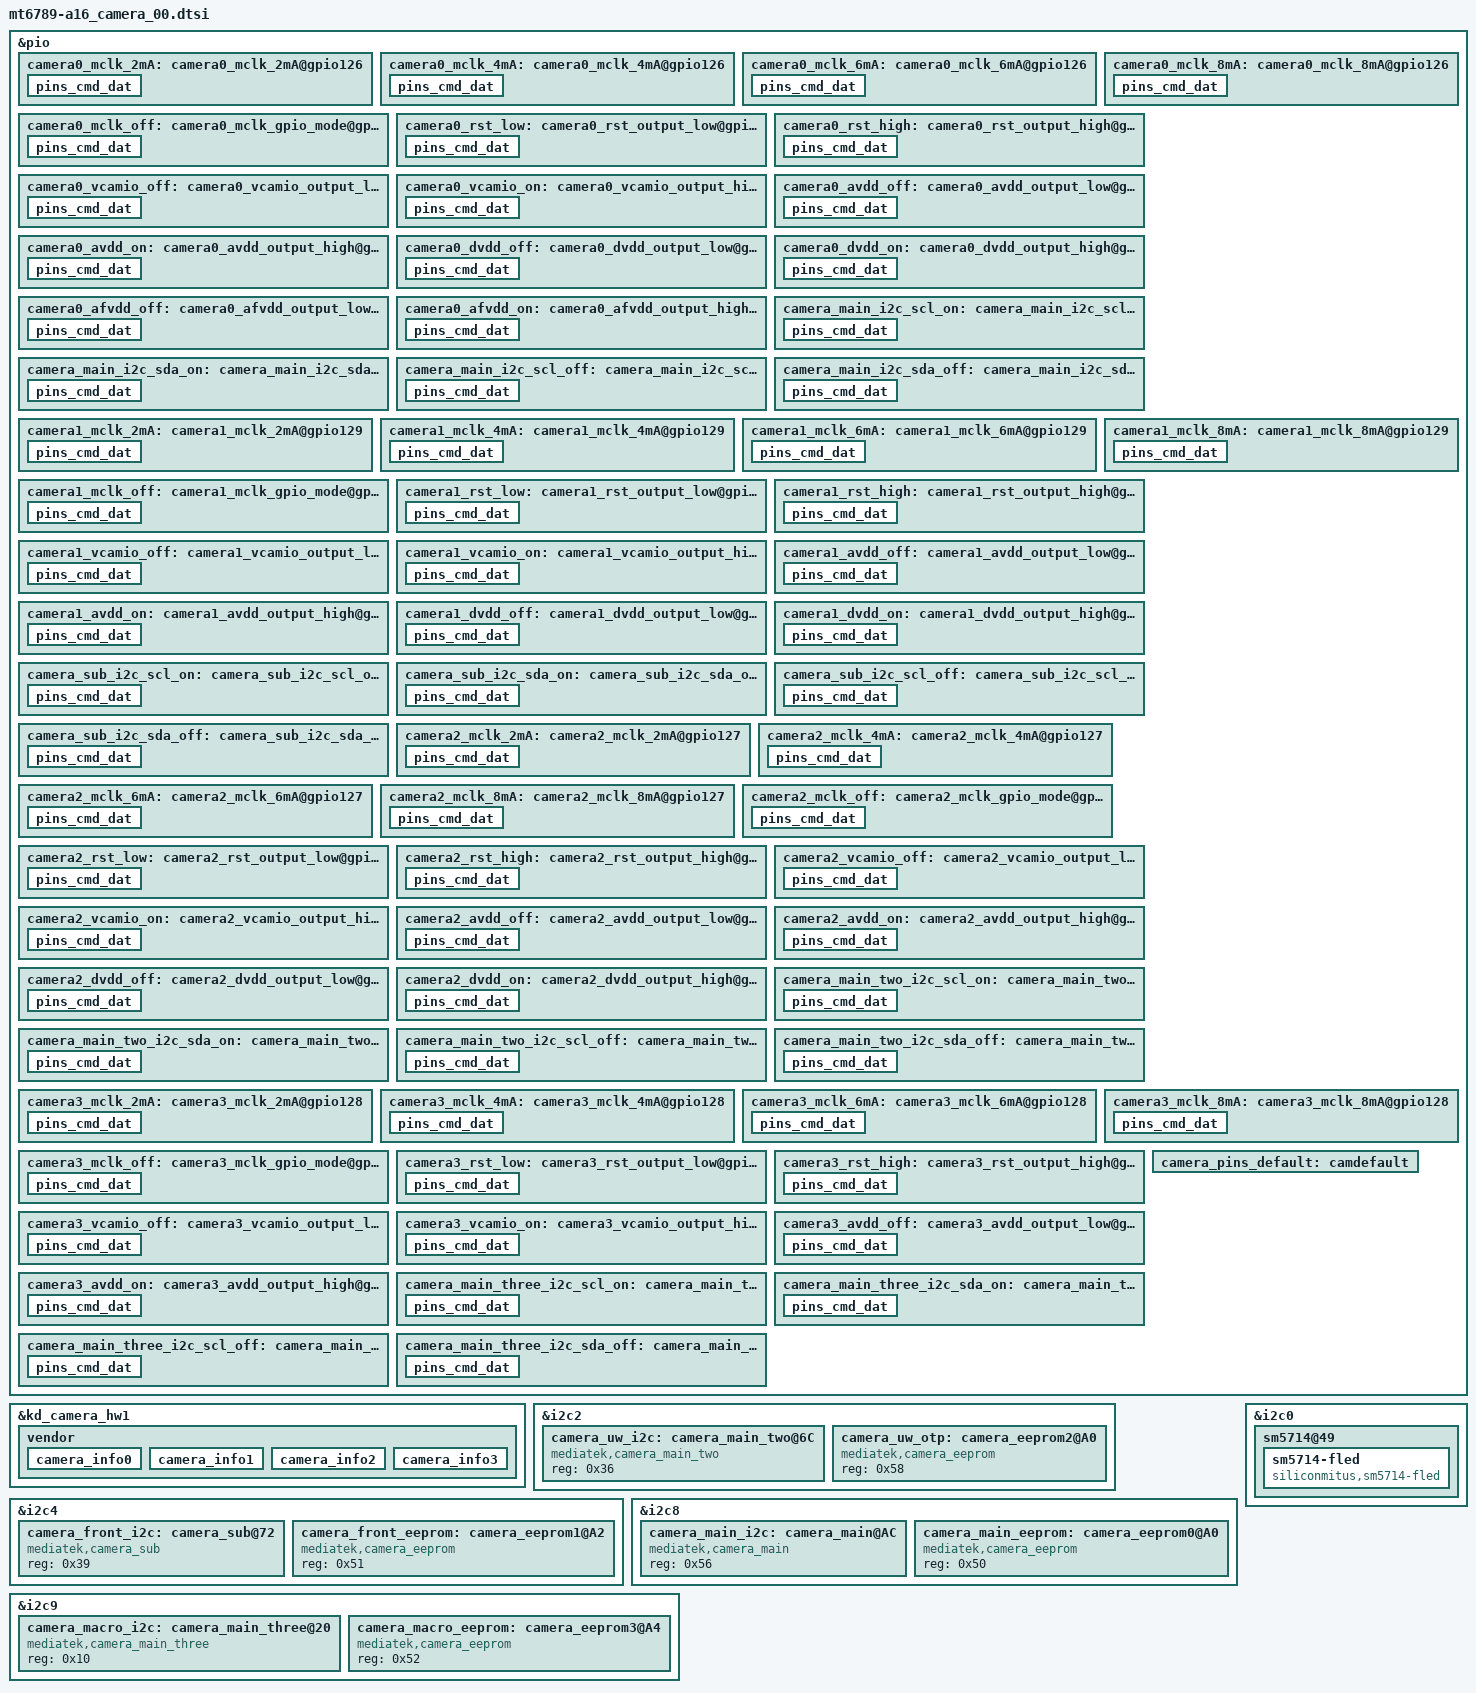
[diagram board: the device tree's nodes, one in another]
/*
 * Copyright (c) 2023 MediaTek Inc.
 *
 * This program is free software; you can redistribute it and/or modify
 * it under the terms of the GNU General Public License version 2 as
 * published by the Free Software Foundation.
 *
 * This program is distributed in the hope that it will be useful,
 * but WITHOUT ANY WARRANTY; without even the implied warranty of
 * MERCHANTABILITY or FITNESS FOR A PARTICULAR PURPOSE.  See the
 * GNU General Public License for more details.
 */

/********  A16-LTE Board  ***********
 *    SW          :   HW   : Sensor
 * camera0(Wide)  : RCAM1  : S5KJN1
 * camera1(Front) : FCAM   : GC13A0
 * camera2(UW)    : RCAM2  : SC501CS
 * camera3(Macro) : RCAM3  : GC02M2
 ***********************************/

/* CAMERA GPIO standardization */
&pio {
	/****************  Camera0  ***************/
	// MCLK
	camera0_mclk_2mA: camera0_mclk_2mA@gpio126 {
		pins_cmd_dat {
			pinmux = <PINMUX_GPIO126__FUNC_CMMCLK0>;
			drive-strength = <0>;
		};
	};
	camera0_mclk_4mA: camera0_mclk_4mA@gpio126 {
		pins_cmd_dat {
			pinmux = <PINMUX_GPIO126__FUNC_CMMCLK0>;
			drive-strength = <1>;
		};
	};
	camera0_mclk_6mA: camera0_mclk_6mA@gpio126 {
		pins_cmd_dat {
			pinmux = <PINMUX_GPIO126__FUNC_CMMCLK0>;
			drive-strength = <2>;
		};
	};
	camera0_mclk_8mA: camera0_mclk_8mA@gpio126 {
		pins_cmd_dat {
			pinmux = <PINMUX_GPIO126__FUNC_CMMCLK0>;
			drive-strength = <3>;
		};
	};
	camera0_mclk_off: camera0_mclk_gpio_mode@gpio126 {
		pins_cmd_dat {
			pinmux = <PINMUX_GPIO126__FUNC_GPIO126>;
			drive-strength = <3>;
		};
	};

	// Reset
	camera0_rst_low: camera0_rst_output_low@gpio16 {
		pins_cmd_dat {
			pinmux = <PINMUX_GPIO16__FUNC_GPIO16>;
			output-low;
		};
	};
	camera0_rst_high: camera0_rst_output_high@gpio16 {
		pins_cmd_dat {
			pinmux = <PINMUX_GPIO16__FUNC_GPIO16>;
			output-high;
		};
	};

	// IOVDD
	camera0_vcamio_off: camera0_vcamio_output_low@gpio108 {
		pins_cmd_dat {
			pinmux = <PINMUX_GPIO108__FUNC_GPIO108>;
			output-low;
		};
	};
	camera0_vcamio_on: camera0_vcamio_output_high@gpio108 {
		pins_cmd_dat {
			pinmux = <PINMUX_GPIO108__FUNC_GPIO108>;
			output-high;
		};
	};

	// AVDD
	camera0_avdd_off: camera0_avdd_output_low@gpio107 {
		pins_cmd_dat {
			pinmux = <PINMUX_GPIO107__FUNC_GPIO107>;
			output-low;
		};
	};
	camera0_avdd_on: camera0_avdd_output_high@gpio107 {
		pins_cmd_dat {
			pinmux = <PINMUX_GPIO107__FUNC_GPIO107>;
			output-high;
		};
	};
	// DVDD
	camera0_dvdd_off: camera0_dvdd_output_low@gpio107 {
		pins_cmd_dat {
			pinmux = <PINMUX_GPIO107__FUNC_GPIO107>;
			output-low;
		};
	};
	camera0_dvdd_on: camera0_dvdd_output_high@gpio107 {
		pins_cmd_dat {
			pinmux = <PINMUX_GPIO107__FUNC_GPIO107>;
			output-high;
		};
	};
	// AFVDD
	camera0_afvdd_off: camera0_afvdd_output_low@gpio107 {
		pins_cmd_dat {
			pinmux = <PINMUX_GPIO107__FUNC_GPIO107>;
			output-low;
		};
	};
	camera0_afvdd_on: camera0_afvdd_output_high@gpio107 {
		pins_cmd_dat {
			pinmux = <PINMUX_GPIO107__FUNC_GPIO107>;
			output-high;
		};
	};

	// I2C
	camera_main_i2c_scl_on: camera_main_i2c_scl_on@gpio146 {
		pins_cmd_dat {
			pinmux = <PINMUX_GPIO146__FUNC_SCL8>;
			bias-disable;
		};
	};
	camera_main_i2c_sda_on: camera_main_i2c_sda_on@gpio147 {
		pins_cmd_dat {
			pinmux = <PINMUX_GPIO147__FUNC_SDA8>;
			bias-disable;
		};
	};
	camera_main_i2c_scl_off: camera_main_i2c_scl_off@gpio146 {
		pins_cmd_dat {
			pinmux = <PINMUX_GPIO146__FUNC_GPIO146>;
			bias-disable;
		};
	};
	camera_main_i2c_sda_off: camera_main_i2c_sda_off@gpio147 {
		pins_cmd_dat {
			pinmux = <PINMUX_GPIO147__FUNC_GPIO147>;
			bias-disable;
		};
	};


	/****************  Camera1  ***************/
	// MCLK
	camera1_mclk_2mA: camera1_mclk_2mA@gpio129 {
		pins_cmd_dat {
			pinmux = <PINMUX_GPIO129__FUNC_CMMCLK3>;
			drive-strength = <0>;
		};
	};
	camera1_mclk_4mA: camera1_mclk_4mA@gpio129 {
		pins_cmd_dat {
			pinmux = <PINMUX_GPIO129__FUNC_CMMCLK3>;
			drive-strength = <1>;
		};
	};
	camera1_mclk_6mA: camera1_mclk_6mA@gpio129 {
		pins_cmd_dat {
			pinmux = <PINMUX_GPIO129__FUNC_CMMCLK3>;
			drive-strength = <2>;
		};
	};
	camera1_mclk_8mA: camera1_mclk_8mA@gpio129 {
		pins_cmd_dat {
			pinmux = <PINMUX_GPIO129__FUNC_CMMCLK3>;
			drive-strength = <3>;
		};
	};
	camera1_mclk_off: camera1_mclk_gpio_mode@gpio129 {
		pins_cmd_dat {
			pinmux = <PINMUX_GPIO129__FUNC_GPIO129>;
			drive-strength = <1>;
		};
	};

	// Reset
	camera1_rst_low: camera1_rst_output_low@gpio15 {
		pins_cmd_dat {
			pinmux = <PINMUX_GPIO15__FUNC_GPIO15>;
			output-low;
		};
	};
	camera1_rst_high: camera1_rst_output_high@gpio15 {
		pins_cmd_dat {
			pinmux = <PINMUX_GPIO15__FUNC_GPIO15>;
			output-high;
		};
	};

	// IOVDD
	camera1_vcamio_off: camera1_vcamio_output_low@gpio108 {
		pins_cmd_dat {
			pinmux = <PINMUX_GPIO108__FUNC_GPIO108>;
			output-low;
		};
	};
	camera1_vcamio_on: camera1_vcamio_output_high@gpio108 {
		pins_cmd_dat {
			pinmux = <PINMUX_GPIO108__FUNC_GPIO108>;
			output-high;
		};
	};

	// AVDD
	camera1_avdd_off: camera1_avdd_output_low@gpio153 {
		pins_cmd_dat {
			pinmux = <PINMUX_GPIO153__FUNC_GPIO153>;
			output-low;
		};
	};
	camera1_avdd_on: camera1_avdd_output_high@gpio153 {
		pins_cmd_dat {
			pinmux = <PINMUX_GPIO153__FUNC_GPIO153>;
			output-high;
		};
	};
	// DVDD
	camera1_dvdd_off: camera1_dvdd_output_low@gpio153 {
		pins_cmd_dat {
			pinmux = <PINMUX_GPIO153__FUNC_GPIO153>;
			output-low;
		};
	};
	camera1_dvdd_on: camera1_dvdd_output_high@gpio153 {
		pins_cmd_dat {
			pinmux = <PINMUX_GPIO153__FUNC_GPIO153>;
			output-high;
		};
	};

	// I2C
	camera_sub_i2c_scl_on: camera_sub_i2c_scl_on@gpio138 {
		pins_cmd_dat {
			pinmux = <PINMUX_GPIO138__FUNC_SCL4>;
			bias-pull-up;
		};
	};
	camera_sub_i2c_sda_on: camera_sub_i2c_sda_on@gpio139 {
		pins_cmd_dat {
			pinmux = <PINMUX_GPIO139__FUNC_SDA4>;
			bias-pull-up;
		};
	};
	camera_sub_i2c_scl_off: camera_sub_i2c_scl_off@gpio138 {
		pins_cmd_dat {
			pinmux = <PINMUX_GPIO138__FUNC_GPIO138>;
			bias-pull-down;
		};
	};
	camera_sub_i2c_sda_off: camera_sub_i2c_sda_off@gpio139 {
		pins_cmd_dat {
			pinmux = <PINMUX_GPIO139__FUNC_GPIO139>;
			bias-pull-down;
		};
	};

	/****************  Camera2  ***************/
	// MCLK
	camera2_mclk_2mA: camera2_mclk_2mA@gpio127 {
		pins_cmd_dat {
			pinmux = <PINMUX_GPIO127__FUNC_CMMCLK1>;
			drive-strength = <0>;
		};
	};
	camera2_mclk_4mA: camera2_mclk_4mA@gpio127 {
		pins_cmd_dat {
			pinmux = <PINMUX_GPIO127__FUNC_CMMCLK1>;
			drive-strength = <1>;
		};
	};
	camera2_mclk_6mA: camera2_mclk_6mA@gpio127 {
		pins_cmd_dat {
			pinmux = <PINMUX_GPIO127__FUNC_CMMCLK1>;
			drive-strength = <2>;
		};
	};
	camera2_mclk_8mA: camera2_mclk_8mA@gpio127 {
		pins_cmd_dat {
			pinmux = <PINMUX_GPIO127__FUNC_CMMCLK1>;
			drive-strength = <3>;
		};
	};
	camera2_mclk_off: camera2_mclk_gpio_mode@gpio127 {
		pins_cmd_dat {
			pinmux = <PINMUX_GPIO127__FUNC_GPIO127>;
			drive-strength = <1>;
		};
	};

	// Reset
	camera2_rst_low: camera2_rst_output_low@gpio18 {
		pins_cmd_dat {
			pinmux = <PINMUX_GPIO18__FUNC_GPIO18>;
			output-low;
		};
	};
	camera2_rst_high: camera2_rst_output_high@gpio18 {
		pins_cmd_dat {
			pinmux = <PINMUX_GPIO18__FUNC_GPIO18>;
			output-high;
		};
	};

	// IOVDD
	camera2_vcamio_off: camera2_vcamio_output_low@gpio108 {
		pins_cmd_dat {
			pinmux = <PINMUX_GPIO108__FUNC_GPIO108>;
			output-low;
		};
	};
	camera2_vcamio_on: camera2_vcamio_output_high@gpio108 {
		pins_cmd_dat {
			pinmux = <PINMUX_GPIO108__FUNC_GPIO108>;
			output-high;
		};
	};

	// AVDD
	camera2_avdd_off: camera2_avdd_output_low@gpio153 {
		pins_cmd_dat {
			pinmux = <PINMUX_GPIO153__FUNC_GPIO153>;
			output-low;
		};
	};
	camera2_avdd_on: camera2_avdd_output_high@gpio153 {
		pins_cmd_dat {
			pinmux = <PINMUX_GPIO153__FUNC_GPIO153>;
			output-high;
		};
	};
	// DVDD
	camera2_dvdd_off: camera2_dvdd_output_low@gpio159 {
		pins_cmd_dat {
			pinmux = <PINMUX_GPIO159__FUNC_GPIO159>;
			output-low;
		};
	};
	camera2_dvdd_on: camera2_dvdd_output_high@gpio159 {
		pins_cmd_dat {
			pinmux = <PINMUX_GPIO159__FUNC_GPIO159>;
			output-high;
		};
	};

	// I2C
	camera_main_two_i2c_scl_on: camera_main_two_i2c_scl_on@gpio134 {
		pins_cmd_dat {
			pinmux = <PINMUX_GPIO134__FUNC_SCL2>;
			bias-pull-up;
		};
	};
	camera_main_two_i2c_sda_on: camera_main_two_i2c_sda_on@gpio135 {
		pins_cmd_dat {
			pinmux = <PINMUX_GPIO135__FUNC_SDA2>;
			bias-pull-up;
		};
	};
	camera_main_two_i2c_scl_off: camera_main_two_i2c_scl_off@gpio134 {
		pins_cmd_dat {
			pinmux = <PINMUX_GPIO134__FUNC_GPIO134>;
			bias-pull-down;
		};
	};
	camera_main_two_i2c_sda_off: camera_main_two_i2c_sda_off@gpio135 {
		pins_cmd_dat {
			pinmux = <PINMUX_GPIO135__FUNC_GPIO135>;
			bias-pull-down;
		};
	};

	/****************  Camera3  ***************/
	// MCLK
	camera3_mclk_2mA: camera3_mclk_2mA@gpio128 {
		pins_cmd_dat {
			pinmux = <PINMUX_GPIO128__FUNC_CMMCLK2>;
			drive-strength = <0>;
		};
	};
	camera3_mclk_4mA: camera3_mclk_4mA@gpio128 {
		pins_cmd_dat {
			pinmux = <PINMUX_GPIO128__FUNC_CMMCLK2>;
			drive-strength = <1>;
		};
	};
	camera3_mclk_6mA: camera3_mclk_6mA@gpio128 {
		pins_cmd_dat {
			pinmux = <PINMUX_GPIO128__FUNC_CMMCLK2>;
			drive-strength = <2>;
		};
	};
	camera3_mclk_8mA: camera3_mclk_8mA@gpio128 {
		pins_cmd_dat {
			pinmux = <PINMUX_GPIO128__FUNC_CMMCLK2>;
			drive-strength = <3>;
		};
	};
	camera3_mclk_off: camera3_mclk_gpio_mode@gpio128 {
		pins_cmd_dat {
			pinmux = <PINMUX_GPIO128__FUNC_GPIO128>;
			drive-strength = <3>;
		};
	};

	// Reset
	camera3_rst_low: camera3_rst_output_low@gpio22 {
		pins_cmd_dat {
			pinmux = <PINMUX_GPIO22__FUNC_GPIO22>;
			output-low;
		};
	};
	camera3_rst_high: camera3_rst_output_high@gpio22 {
		pins_cmd_dat {
			pinmux = <PINMUX_GPIO22__FUNC_GPIO22>;
			output-high;
		};
	};

	// IOVDD
	camera3_vcamio_off: camera3_vcamio_output_low@gpio108 {
		pins_cmd_dat {
			pinmux = <PINMUX_GPIO108__FUNC_GPIO108>;
			output-low;
		};
	};
	camera3_vcamio_on: camera3_vcamio_output_high@gpio108 {
		pins_cmd_dat {
			pinmux = <PINMUX_GPIO108__FUNC_GPIO108>;
			output-high;
		};
	};

	// AVDD
	camera3_avdd_off: camera3_avdd_output_low@gpio153 {
		pins_cmd_dat {
			pinmux = <PINMUX_GPIO153__FUNC_GPIO153>;
			output-low;
		};
	};
	camera3_avdd_on: camera3_avdd_output_high@gpio153 {
		pins_cmd_dat {
			pinmux = <PINMUX_GPIO153__FUNC_GPIO153>;
			output-high;
		};
	};

	// I2C
	camera_main_three_i2c_scl_on: camera_main_three_i2c_scl_on@gpio148 {
		pins_cmd_dat {
			pinmux = <PINMUX_GPIO148__FUNC_SCL9>;
			bias-pull-up;
		};
	};
	camera_main_three_i2c_sda_on: camera_main_three_i2c_sda_on@gpio149 {
		pins_cmd_dat {
			pinmux = <PINMUX_GPIO149__FUNC_SDA9>;
			bias-pull-up;
		};
	};
	camera_main_three_i2c_scl_off: camera_main_three_i2c_scl_off@gpio148 {
		pins_cmd_dat {
			pinmux = <PINMUX_GPIO148__FUNC_GPIO148>;
			bias-pull-down;
		};
	};
	camera_main_three_i2c_sda_off: camera_main_three_i2c_sda_off@gpio149 {
		pins_cmd_dat {
			pinmux = <PINMUX_GPIO149__FUNC_GPIO149>;
			bias-pull-down;
		};
	};

/****************  default  ***************/
	camera_pins_default: camdefault {
	};
};

&kd_camera_hw1 {
	pinctrl-names = "default",
			"cam0_mclk_off",
			"cam0_mclk_2mA",  "cam0_mclk_4mA",
			"cam0_mclk_6mA",  "cam0_mclk_8mA",
			"cam0_rst0",       "cam0_rst1",
			"cam0_vcamio_off", "cam0_vcamio_on",
			"cam0_vcamd_off",   "cam0_vcamd_on",
			"cam0_vcama_off",   "cam0_vcama_on",
			"cam0_vcamaf_off",  "cam0_vcamaf_on",

			"cam1_mclk_off",
			"cam1_mclk_2mA", "cam1_mclk_4mA",
			"cam1_mclk_6mA", "cam1_mclk_8mA",
			"cam1_rst0", "cam1_rst1",
			"cam1_vcamio_off", "cam1_vcamio_on",
			"cam1_vcama_off",   "cam1_vcama_on",
			"cam1_vcamd_off",   "cam1_vcamd_on",

			"cam2_mclk_off",
			"cam2_mclk_2mA", "cam2_mclk_4mA",
			"cam2_mclk_6mA", "cam2_mclk_8mA",
			"cam2_rst0", "cam2_rst1",
			"cam2_vcamio_off", "cam2_vcamio_on",
			"cam2_vcama_off",   "cam2_vcama_on",
			"cam2_vcamd_off",   "cam2_vcamd_on",

			"cam3_mclk_off",
			"cam3_mclk_2mA", "cam3_mclk_4mA",
			"cam3_mclk_6mA", "cam3_mclk_8mA",
			"cam3_rst0", "cam3_rst1",
			"cam3_vcamio_off", "cam3_vcamio_on",
			"cam3_vcama_off",   "cam3_vcama_on";

	pinctrl-0 = <&camera_pins_default>;

	pinctrl-1 = <&camera0_mclk_off>;
	pinctrl-2 = <&camera0_mclk_2mA>;
	pinctrl-3 = <&camera0_mclk_4mA>;
	pinctrl-4 = <&camera0_mclk_6mA>;
	pinctrl-5 = <&camera0_mclk_8mA>;
	pinctrl-6 = <&camera0_rst_low>;
	pinctrl-7 = <&camera0_rst_high>;
	pinctrl-8 = <&camera0_vcamio_off>;
	pinctrl-9 = <&camera0_vcamio_on>;
	pinctrl-10 = <&camera0_dvdd_off>;
	pinctrl-11 = <&camera0_dvdd_on>;
	pinctrl-12 = <&camera0_avdd_off>;
	pinctrl-13 = <&camera0_avdd_on>;
	pinctrl-14 = <&camera0_afvdd_off>;
	pinctrl-15 = <&camera0_afvdd_on>;

	pinctrl-16 = <&camera1_mclk_off>;
	pinctrl-17 = <&camera1_mclk_2mA>;
	pinctrl-18 = <&camera1_mclk_4mA>;
	pinctrl-19 = <&camera1_mclk_6mA>;
	pinctrl-20 = <&camera1_mclk_8mA>;
	pinctrl-21 = <&camera1_rst_low>;
	pinctrl-22 = <&camera1_rst_high>;
	pinctrl-23 = <&camera1_vcamio_off>;
	pinctrl-24 = <&camera1_vcamio_on>;
	pinctrl-25 = <&camera1_avdd_off>;
	pinctrl-26 = <&camera1_avdd_on>;
	pinctrl-27 = <&camera1_dvdd_off>;
	pinctrl-28 = <&camera1_dvdd_on>;

	pinctrl-29 = <&camera2_mclk_off>;
	pinctrl-30 = <&camera2_mclk_2mA>;
	pinctrl-31 = <&camera2_mclk_4mA>;
	pinctrl-32 = <&camera2_mclk_6mA>;
	pinctrl-33 = <&camera2_mclk_8mA>;
	pinctrl-34 = <&camera2_rst_low>;
	pinctrl-35 = <&camera2_rst_high>;
	pinctrl-36 = <&camera2_vcamio_off>;
	pinctrl-37 = <&camera2_vcamio_on>;
	pinctrl-38 = <&camera2_avdd_off>;
	pinctrl-39 = <&camera2_avdd_on>;
	pinctrl-40 = <&camera2_dvdd_off>;
	pinctrl-41 = <&camera2_dvdd_on>;

	pinctrl-42 = <&camera3_mclk_off>;
	pinctrl-43 = <&camera3_mclk_2mA>;
	pinctrl-44 = <&camera3_mclk_4mA>;
	pinctrl-45 = <&camera3_mclk_6mA>;
	pinctrl-46 = <&camera3_mclk_8mA>;
	pinctrl-47 = <&camera3_rst_low>;
	pinctrl-48 = <&camera3_rst_high>;
	pinctrl-49 = <&camera3_vcamio_off>;
	pinctrl-50 = <&camera3_vcamio_on>;
	pinctrl-51 = <&camera3_avdd_off>;
	pinctrl-52 = <&camera3_avdd_on>;

	status = "okay";
	vendor {
		rear_sensor_id = <120>;     /* SENSOR_NAME_S5KJN1 */
		front_sensor_id = <121>;    /* SENSOR_NAME_GC13A0 */
		rear2_sensor_id = <210>;    /* SENSOR_NAME_SC501CS */
		rear3_sensor_id = <211>;    /* SENSOR_NAME_GC02M2 */

		//use_dualcam_set_cal;
		//use_module_check;
		//skip_cal_loading;         /* for test without cal loading */
		check_final_cam_module;   /* use after DVR */
		max_supported_camera = <4>;
		supported_cameraId = <56 1 58 60>; /* REAR, FRONT, REAR2, REAR3 */

		max_camera_num = <4>;
		camera_info0 {             /* 0 : rear - HI5022Q */
			isp = <0>;             /* 0 : INT , 1 : EXT , 2 : SOC */
			cal_memory = <2>;      /* 0 : N , 1 : FROM , 2 : EEPROM , 3 : OTP  */
			read_version = <0>;    /* 0 : SYSFS , 1 : CAMON */
			core_voltage = <0>;    /* 0 : N , 1 : Y  */
			upgrade = <0>;         /* 0 : N , 1 : SYSFS , 2 : CAMON */
			companion = <0>;       /* 0 : N , 1 : Y  */
			ois = <0>;             /* 0 : N , 1 : Y  */
			valid = <1>;           /* 0 : INVALID, 1 : VALID */
			dual_open = <0>;       /* 0 : SINGLE_OPEN , 1 : DUAL_OPEN */
			position = <0>;        /* 0 : Rear, 1:Front, 2:Rear2, 3:Front2, 4:Rear3, 6:Rear4 */
			//includes_sub = <4>;    /* include this for common eeprom. <_position_> - position of the sub camera */
			afcal_type=<20>;       /* output format - 1: Near, Middle..., Far , 20: Near, Far, Middle... */
			use_adaptive_mipi=<1>;  /* 0 : N, 1 : Y */
		};
		camera_info1 {             /* 1 : front1 - GC13A0 */
			isp = <0>;             /* 0 : INT , 1 : EXT , 2 : SOC */
			cal_memory = <2>;      /* 0 : N , 1 : FROM , 2 : EEPROM , 3 : OTP  */
			read_version = <0>;    /* 0 : SYSFS , 1 : CAMON */
			core_voltage = <0>;    /* 0 : N , 1 : Y  */
			upgrade = <0>;         /* 0 : N , 1 : SYSFS , 2 : CAMON */
			companion = <0>;       /* 0 : N , 1 : Y  */
			ois = <0>;             /* 0 : N , 1 : Y  */
			valid = <1>;           /* 0 : INVALID, 1 : VALID */
			dual_open = <0>;       /* 0 : SINGLE_OPEN , 1 : DUAL_OPEN */
			position = <1>;        /* 0 : Rear, 1:Front, 2:Rear2, 3:Front2, 4:Rear3, 6:Rear4 */
			use_adaptive_mipi=<1>;  /* 0 : N, 1 : Y */
		};
		camera_info2 {             /* 2 : rear2 - SC501CS */
			isp = <0>;             /* 0 : INT , 1 : EXT , 2 : SOC */
			cal_memory = <3>;      /* 0 : N , 1 : FROM , 2 : EEPROM , 3 : OTP  */
			read_version = <0>;    /* 0 : SYSFS , 1 : CAMON */
			core_voltage = <0>;    /* 0 : N , 1 : Y  */
			upgrade = <0>;         /* 0 : N , 1 : SYSFS , 2 : CAMON */
			companion = <0>;       /* 0 : N , 1 : Y  */
			ois = <0>;             /* 0 : N , 1 : Y  */
			valid = <1>;           /* 0 : INVALID, 1 : VALID */
			dual_open = <0>;       /* 0 : SINGLE_OPEN , 1 : DUAL_OPEN */
			position = <2>;        /* 0 : Rear, 1:Front, 2:Rear2, 3:Front2, 4:Rear3, 6:Rear4 */
			use_adaptive_mipi=<0>;  /* 0 : N, 1 : Y */
		};
		camera_info3{             /* 3 : rear3 - GC02M2 */
			isp = <0>;             /* 0 : INT , 1 : EXT , 2 : SOC */
			cal_memory = <2>;      /* 0 : N , 1 : FROM , 2 : EEPROM , 3 : OTP  */
			read_version = <0>;    /* 0 : SYSFS , 1 : CAMON */
			core_voltage = <0>;    /* 0 : N , 1 : Y  */
			upgrade = <0>;         /* 0 : N , 1 : SYSFS , 2 : CAMON */
			companion = <0>;       /* 0 : N , 1 : Y  */
			ois = <0>;             /* 0 : N , 1 : Y  */
			valid = <1>;           /* 0 : INVALID, 1 : VALID */
			dual_open = <0>;       /* 0 : SINGLE_OPEN , 1 : DUAL_OPEN */
			position = <4>;        /* 0 : Rear, 1:Front, 2:Rear2, 3:Front2, 4:Rear3, 6:Rear4 */
			use_adaptive_mipi=<0>;  /* 0 : N, 1 : Y */
		};
	};
};
/* CAMERA GPIO end */

/*************************
 *     Cmaera I2C
 *************************/
&i2c2 {
	status = "okay";
	#address-cells = <1>;
	#size-cells = <0>;
	clock-frequency = <400000>;
	mediatek,use-open-drain;

	pinctrl-names = "default";
	camera_uw_i2c:camera_main_two@6C{
		compatible = "mediatek,camera_main_two";
		reg = <0x36>;
		status = "okay";
	};
	camera_uw_otp:camera_eeprom2@A0 {
		compatible = "mediatek,camera_eeprom";
		reg = <0x58>;
		status = "okay";
	};
};

&i2c4 {
	status = "okay";
	#address-cells = <1>;
	#size-cells = <0>;
	clock-frequency = <1000000>;
	mediatek,use-open-drain;
	camera_front_i2c:camera_sub@72 {
		compatible = "mediatek,camera_sub";
		reg = <0x39>;
		status = "okay";
	};
	camera_front_eeprom:camera_eeprom1@A2 {
		compatible = "mediatek,camera_eeprom";
		reg = <0x51>;
		status = "okay";
	};
};

&i2c8 {
	status = "okay";
	#address-cells = <1>;
	#size-cells = <0>;
	clock-frequency = <1000000>;
	mediatek,use-open-drain;

	camera_main_i2c:camera_main@AC{
		compatible = "mediatek,camera_main";
		reg = <0x56>;
		status = "okay";
	};
	camera_main_eeprom:camera_eeprom0@A0 {
		compatible = "mediatek,camera_eeprom";
		reg = <0x50>;
		status = "okay";
	};
};
&i2c9 {
	status = "okay";
	#address-cells = <1>;
	#size-cells = <0>;
	clock-frequency = <400000>;
	mediatek,use-open-drain;

	camera_macro_i2c:camera_main_three@20 {
		compatible = "mediatek,camera_main_three";
		reg = <0x10>;
		status = "okay";
	};
	camera_macro_eeprom:camera_eeprom3@A4 {
		compatible = "mediatek,camera_eeprom";
		reg = <0x52>;
		status = "okay";
	};	
};

&i2c0 {
	sm5714@49 {
		sm5714-fled {
			status = "okay";
			compatible = "siliconmitus,sm5714-fled";
			flash-en-gpio = <&pio 150 0>;
			torch-en-gpio = <&pio 151 0>;

			flash-brightness = <0xA>; //0x0(300mA) ~ 0xF(1500mA) : 50mA Step
			preflash-brightness = <0x4>;
			torch-brightness = <0x4>; //0x0(50mA) ~ 0x7(225mA) : 25mA Step
			factory_current = <0x6>; //0x0(300mA)
			flashlight_current = <0 1 2 5 7>;
			timeout = <0xff>;
		};
	};
};

